AUTOSAR XML (schema 4-2-2)
package /ASWC
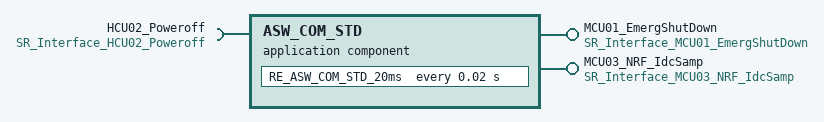
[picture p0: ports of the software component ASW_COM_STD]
  application sw component type ASW_COM_STD
    provide port MCU01_EmergShutDown: provided-interface=SR_Interface_MCU01_EmergShutDown
    provide port MCU03_NRF_IdcSamp: provided-interface=SR_Interface_MCU03_NRF_IdcSamp
    require port HCU02_Poweroff: nonqueued-receiver-com-spec{data-element=DE_HCU02_Poweroff, alive-timeout=0.3}, required-interface=SR_Interface_HCU02_Poweroff
    behavior IB_ASW_COM_STD
      timing event TE_ASW_COM_STD_20ms: start-on-event=RE_ASW_COM_STD_20ms, period=0.02
      runnable RE_ASW_COM_STD_20ms
        data-read-access-points:
          access VA_Read_HCU02_Poweroff: accessed-variable=HCU02_Poweroff.DE_HCU02_Poweroff
        data-write-access-points:
          access VA_Write_MCU01_EmergShutDown: accessed-variable=MCU01_EmergShutDown.DE_MCU01_EmergShutDown
          access VA_Write_MCU03_NRF_IdcSamp: accessed-variable=MCU03_NRF_IdcSamp.DE_MCU03_NRF_IdcSamp
